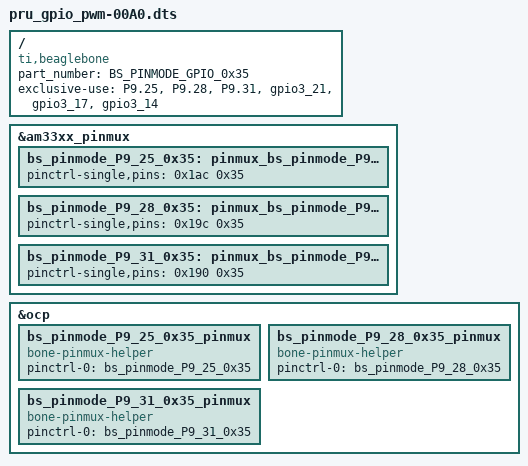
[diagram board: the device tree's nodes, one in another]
/*
 * This is a template-generated file from BoneScript
 */

/dts-v1/;
/plugin/;

/{
    compatible = "ti,beaglebone", "ti,beaglebone-black";
    part_number = "BS_PINMODE_GPIO_0x35";

    exclusive-use =
        "P9.25",
        "P9.28",
        "P9.31",
        "gpio3_21",
        "gpio3_17",
        "gpio3_14";

    fragment@0 {
        target = <&am33xx_pinmux>;
        __overlay__ {
            bs_pinmode_P9_25_0x35: pinmux_bs_pinmode_P9_25_0x35 {
                pinctrl-single,pins = <0x1ac 0x35>;
            };
            bs_pinmode_P9_28_0x35: pinmux_bs_pinmode_P9_28_0x35 {
                pinctrl-single,pins = <0x19c 0x35>;
            };
            bs_pinmode_P9_31_0x35: pinmux_bs_pinmode_P9_31_0x35 {
                pinctrl-single,pins = <0x190 0x35>;
            };
        };
    };

    fragment@1 {
        target = <&ocp>;
        __overlay__ {
            bs_pinmode_P9_25_0x35_pinmux {
                compatible = "bone-pinmux-helper";
                status = "okay";
                pinctrl-names = "default";
                pinctrl-0 = <&bs_pinmode_P9_25_0x35>;
            };
            bs_pinmode_P9_28_0x35_pinmux {
                compatible = "bone-pinmux-helper";
                status = "okay";
                pinctrl-names = "default";
                pinctrl-0 = <&bs_pinmode_P9_28_0x35>;
            };
            bs_pinmode_P9_31_0x35_pinmux {
                compatible = "bone-pinmux-helper";
                status = "okay";
                pinctrl-names = "default";
                pinctrl-0 = <&bs_pinmode_P9_31_0x35>;
            };
        };
    };
};
